AUTOSAR XML (schema 4-2-2)
package /STELLANTIS/EPT/ASWCs
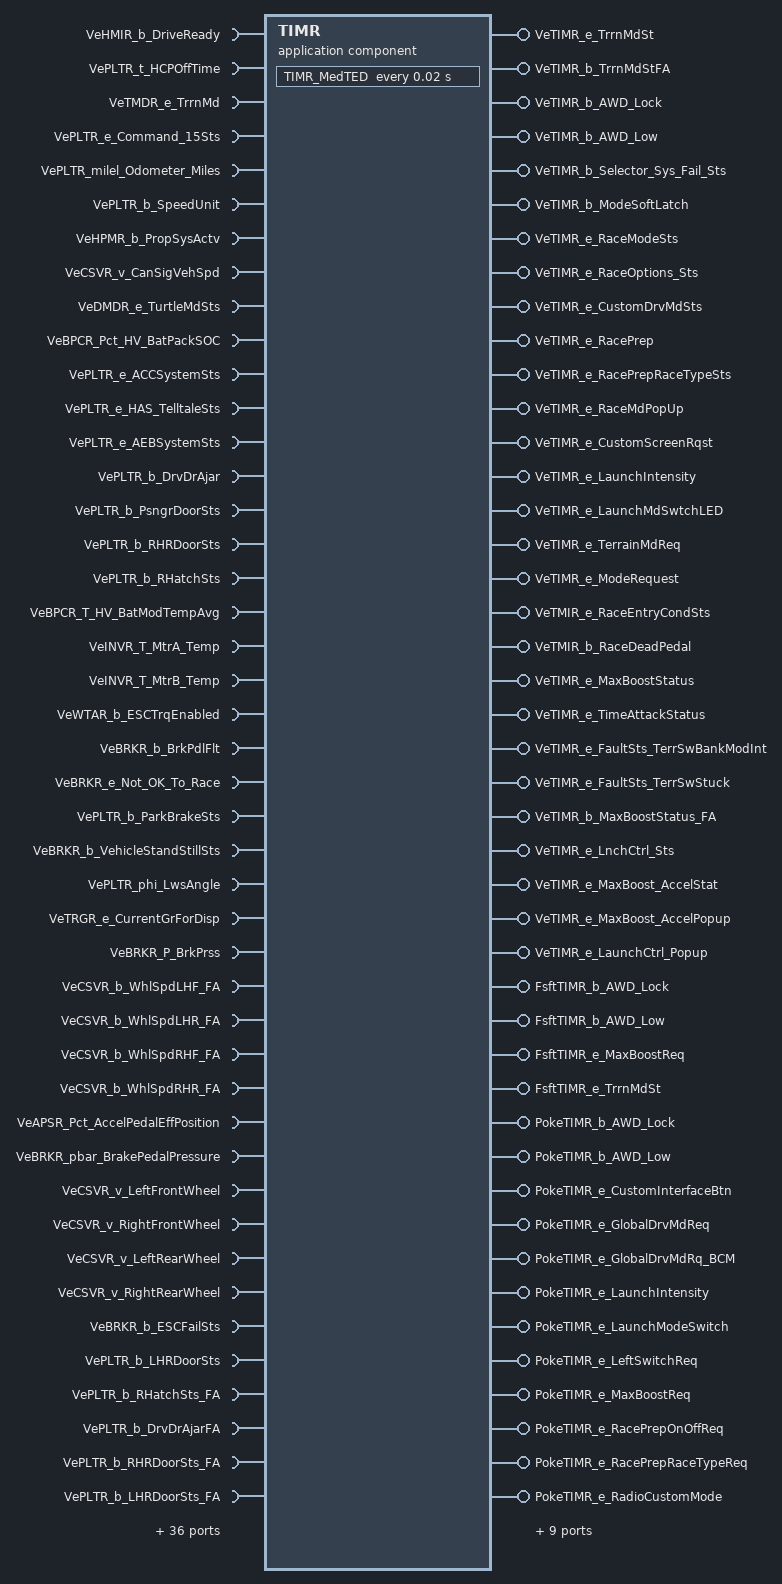
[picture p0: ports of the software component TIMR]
  application sw component type TIMR
    76 x require port:
      VeHMIR_b_DriveReady: nonqueued-receiver-com-spec{data-element=Value, init-value=0}, required-interface=VeHMIR_b_DriveReady
      VePLTR_t_HCPOffTime: nonqueued-receiver-com-spec{data-element=Value, init-value=0}, required-interface=VePLTR_t_HCPOffTime
      VeTMDR_e_TrrnMd: nonqueued-receiver-com-spec{data-element=Value, init-value=CeTMDR_e_NotDefine}, required-interface=VeTMDR_e_TrrnMd
      VePLTR_e_Command_15Sts: variation-point={short-label=vpVePLTR_e_Command_15Sts, sw-syscond=1}, nonqueued-receiver-com-spec{data-element=Value, init-value=CePLTR_e_Not_Pressed}, required-interface=VePLTR_e_Command_15Sts
      VePLTR_milel_Odometer_Miles: nonqueued-receiver-com-spec{data-element=Value, init-value=0}, required-interface=VePLTR_milel_Odometer_Miles
      VePLTR_b_SpeedUnit: variation-point={short-label=vpVePLTR_b_SpeedUnit, sw-syscond=1}, nonqueued-receiver-com-spec{data-element=Value, init-value=0}, required-interface=VePLTR_b_SpeedUnit
      VeHPMR_b_PropSysActv: nonqueued-receiver-com-spec{data-element=Value, init-value=0}, required-interface=VeHPMR_b_PropSysActv
      VeCSVR_v_CanSigVehSpd: nonqueued-receiver-com-spec{data-element=Value, init-value=0}, required-interface=VeCSVR_v_CanSigVehSpd
      VeDMDR_e_TurtleMdSts: nonqueued-receiver-com-spec{data-element=Value, init-value=CeDMDR_e_No_Turtle_Mode}, required-interface=VeDMDR_e_TurtleMdSts
      VeBPCR_Pct_HV_BatPackSOC: nonqueued-receiver-com-spec{data-element=Value, init-value=0}, required-interface=VeBPCR_Pct_HV_BatPackSOC
      VePLTR_e_ACCSystemSts: nonqueued-receiver-com-spec{data-element=Value, init-value=CePLTR_e_Off}, required-interface=VePLTR_e_ACCSystemSts
      VePLTR_e_HAS_TelltaleSts: nonqueued-receiver-com-spec{data-element=Value, init-value=CePLTR_e_HAS_TelltaleSts_OFF}, required-interface=VePLTR_e_HAS_TelltaleSts
      VePLTR_e_AEBSystemSts: nonqueued-receiver-com-spec{data-element=Value, init-value=CePLTR_e_FCW_Off}, required-interface=VePLTR_e_AEBSystemSts
      VePLTR_b_DrvDrAjar: nonqueued-receiver-com-spec{data-element=Value, init-value=0}, required-interface=VePLTR_b_DrvDrAjar
      VePLTR_b_PsngrDoorSts: variation-point={short-label=vpVePLTR_b_PsngrDoorSts, sw-syscond=1}, nonqueued-receiver-com-spec{data-element=Value, init-value=0}, required-interface=VePLTR_b_PsngrDoorSts
      VePLTR_b_RHRDoorSts: variation-point={short-label=vpVePLTR_b_RHRDoorSts, sw-syscond=1}, nonqueued-receiver-com-spec{data-element=Value, init-value=0}, required-interface=VePLTR_b_RHRDoorSts
      VePLTR_b_RHatchSts: variation-point={short-label=vpVePLTR_b_RHatchSts, sw-syscond=1}, nonqueued-receiver-com-spec{data-element=Value, init-value=0}, required-interface=VePLTR_b_RHatchSts
      VeBPCR_T_HV_BatModTempAvg: nonqueued-receiver-com-spec{data-element=Value, init-value=0}, required-interface=VeBPCR_T_HV_BatModTempAvg
      VeINVR_T_MtrA_Temp: nonqueued-receiver-com-spec{data-element=Value, init-value=0}, required-interface=VeINVR_T_MtrA_Temp
      VeINVR_T_MtrB_Temp: nonqueued-receiver-com-spec{data-element=Value, init-value=0}, required-interface=VeINVR_T_MtrB_Temp
      VeWTAR_b_ESCTrqEnabled: variation-point={short-label=vpVeWTAR_b_ESCTrqEnabled, sw-syscond=1}, nonqueued-receiver-com-spec{data-element=Value, init-value=0}, required-interface=VeWTAR_b_ESCTrqEnabled
      VeBRKR_b_BrkPdlFlt: nonqueued-receiver-com-spec{data-element=Value, init-value=0}, required-interface=VeBRKR_b_BrkPdlFlt
      VeBRKR_e_Not_OK_To_Race: variation-point={short-label=vpVeBRKR_e_Not_OK_To_Race, sw-syscond=1}, nonqueued-receiver-com-spec{data-element=Value, init-value=CeBRKR_e_OK}, required-interface=VeBRKR_e_Not_OK_To_Race
      VePLTR_b_ParkBrakeSts: nonqueued-receiver-com-spec{data-element=Value, init-value=0}, required-interface=VePLTR_b_ParkBrakeSts
      VeBRKR_b_VehicleStandStillSts: variation-point={short-label=vpVeBRKR_b_VehicleStandStillSts, sw-syscond=1}, nonqueued-receiver-com-spec{data-element=Value, init-value=0}, required-interface=VeBRKR_b_VehicleStandStillSts
      VePLTR_phi_LwsAngle: nonqueued-receiver-com-spec{data-element=Value, init-value=0}, required-interface=VePLTR_phi_LwsAngle
      VeTRGR_e_CurrentGrForDisp: nonqueued-receiver-com-spec{data-element=Value, init-value=0}, required-interface=VeTRGR_e_CurrentGrForDisp
      VeBRKR_P_BrkPrss: nonqueued-receiver-com-spec{data-element=Value, init-value=0}, required-interface=VeBRKR_P_BrkPrss
      VeCSVR_b_WhlSpdLHF_FA: nonqueued-receiver-com-spec{data-element=Value, init-value=0}, required-interface=VeCSVR_b_WhlSpdLHF_FA
      VeCSVR_b_WhlSpdLHR_FA: nonqueued-receiver-com-spec{data-element=Value, init-value=0}, required-interface=VeCSVR_b_WhlSpdLHR_FA
      VeCSVR_b_WhlSpdRHF_FA: nonqueued-receiver-com-spec{data-element=Value, init-value=0}, required-interface=VeCSVR_b_WhlSpdRHF_FA
      VeCSVR_b_WhlSpdRHR_FA: nonqueued-receiver-com-spec{data-element=Value, init-value=0}, required-interface=VeCSVR_b_WhlSpdRHR_FA
      VeAPSR_Pct_AccelPedalEffPosition: nonqueued-receiver-com-spec{data-element=Value, init-value=0}, required-interface=VeAPSR_Pct_AccelPedalEffPosition
      VeBRKR_pbar_BrakePedalPressure: nonqueued-receiver-com-spec{data-element=Value, init-value=0}, required-interface=VeBRKR_pbar_BrakePedalPressure
      VeCSVR_v_LeftFrontWheel: nonqueued-receiver-com-spec{data-element=Value, init-value=0}, required-interface=VeCSVR_v_LeftFrontWheel
      VeCSVR_v_RightFrontWheel: nonqueued-receiver-com-spec{data-element=Value, init-value=0}, required-interface=VeCSVR_v_RightFrontWheel
      VeCSVR_v_LeftRearWheel: nonqueued-receiver-com-spec{data-element=Value, init-value=0}, required-interface=VeCSVR_v_LeftRearWheel
      VeCSVR_v_RightRearWheel: nonqueued-receiver-com-spec{data-element=Value, init-value=0}, required-interface=VeCSVR_v_RightRearWheel
      VeBRKR_b_ESCFailSts: variation-point={short-label=vpVeBRKR_b_ESCFailSts, sw-syscond=1}, nonqueued-receiver-com-spec{data-element=Value, init-value=0}, required-interface=VeBRKR_b_ESCFailSts
      VePLTR_b_LHRDoorSts: variation-point={short-label=vpVePLTR_b_LHRDoorSts, sw-syscond=1}, nonqueued-receiver-com-spec{data-element=Value, init-value=0}, required-interface=VePLTR_b_LHRDoorSts
      VePLTR_b_RHatchSts_FA: variation-point={short-label=vpVePLTR_b_RHatchSts_FA, sw-syscond=1}, nonqueued-receiver-com-spec{data-element=Value, init-value=0}, required-interface=VePLTR_b_RHatchSts_FA
      VePLTR_b_DrvDrAjarFA: nonqueued-receiver-com-spec{data-element=Value, init-value=0}, required-interface=VePLTR_b_DrvDrAjarFA
      VePLTR_b_RHRDoorSts_FA: variation-point={short-label=vpVePLTR_b_RHRDoorSts_FA, sw-syscond=1}, nonqueued-receiver-com-spec{data-element=Value, init-value=0}, required-interface=VePLTR_b_RHRDoorSts_FA
      VePLTR_b_LHRDoorSts_FA: variation-point={short-label=vpVePLTR_b_LHRDoorSts_FA, sw-syscond=1}, nonqueued-receiver-com-spec{data-element=Value, init-value=0}, required-interface=VePLTR_b_LHRDoorSts_FA
      VePLTR_b_PsngrDoorSts_FA: variation-point={short-label=vpVePLTR_b_PsngrDoorSts_FA, sw-syscond=1}, nonqueued-receiver-com-spec{data-element=Value, init-value=0}, required-interface=VePLTR_b_PsngrDoorSts_FA
      VePLTR_b_SpeedUnit_FA: variation-point={short-label=vpVePLTR_b_SpeedUnit_FA, sw-syscond=1}, nonqueued-receiver-com-spec{data-element=Value, init-value=0}, required-interface=VePLTR_b_SpeedUnit_FA
      VeCSVR_b_CanSigVehSpd_FA: nonqueued-receiver-com-spec{data-element=Value, init-value=0}, required-interface=VeCSVR_b_CanSigVehSpd_FA
      VeBPCR_b_HV_BatPackSOC_FA: nonqueued-receiver-com-spec{data-element=Value, init-value=0}, required-interface=VeBPCR_b_HV_BatPackSOC_FA
      VePLTR_b_ACCSystemSts_FA: nonqueued-receiver-com-spec{data-element=Value, init-value=0}, required-interface=VePLTR_b_ACCSystemSts_FA
      VePLTR_b_HAS_TelltaleSts_FA: nonqueued-receiver-com-spec{data-element=Value, init-value=0}, required-interface=VePLTR_b_HAS_TelltaleSts_FA
      VePLTR_b_AEBSystemSts_FA: nonqueued-receiver-com-spec{data-element=Value, init-value=0}, required-interface=VePLTR_b_AEBSystemSts_FA
      VeBPCR_b_HV_BatModTempAvgFA: nonqueued-receiver-com-spec{data-element=Value, init-value=0}, required-interface=VeBPCR_b_HV_BatModTempAvgFA
      VeINVR_b_MtrB_TempFA: nonqueued-receiver-com-spec{data-element=Value, init-value=0}, required-interface=VeINVR_b_MtrB_TempFA
      VeINVR_b_MtrA_TempFA: nonqueued-receiver-com-spec{data-element=Value, init-value=0}, required-interface=VeINVR_b_MtrA_TempFA
      VeBRKR_b_Not_OK_To_RaceFA: variation-point={short-label=vpVeBRKR_b_Not_OK_To_RaceFA, sw-syscond=1}, nonqueued-receiver-com-spec{data-element=Value, init-value=0}, required-interface=VeBRKR_b_Not_OK_To_RaceFA
      VeSRAR_b_Inhibit_AWD_TerrainMode: nonqueued-receiver-com-spec{data-element=Value, init-value=0}, required-interface=VeSRAR_b_Inhibit_AWD_TerrainMode
      VePRXR_b_Proxi_Custom_Mode: nonqueued-receiver-com-spec{data-element=Value, init-value=0}, required-interface=VePRXR_b_Proxi_Custom_Mode
      VePRXR_b_Proxi_Track_Mode: nonqueued-receiver-com-spec{data-element=Value, init-value=0}, required-interface=VePRXR_b_Proxi_Track_Mode
      VePRXR_e_Axle_Locker_Presence: nonqueued-receiver-com-spec{data-element=Value, init-value=CePRXR_e_ALP_Absent}, required-interface=VePRXR_e_Axle_Locker_Presence
      VePRXR_e_Terrain_Selector_Modes: nonqueued-receiver-com-spec{data-element=Value, init-value=CePRXR_e_Invalid}, required-interface=VePRXR_e_Terrain_Selector_Modes
      VeINVR_T_MtrA_InvrtrTemp: nonqueued-receiver-com-spec{data-element=Value, init-value=0}, required-interface=VeINVR_T_MtrA_InvrtrTemp
      VeINVR_T_MtrB_InvrtrTemp: nonqueued-receiver-com-spec{data-element=Value, init-value=0}, required-interface=VeINVR_T_MtrB_InvrtrTemp
      VeINVR_b_MtrA_InvrtrTempFA: nonqueued-receiver-com-spec{data-element=Value, init-value=0}, required-interface=VeINVR_b_MtrA_InvrtrTempFA
      VeINVR_b_MtrB_InvrtrTempFA: nonqueued-receiver-com-spec{data-element=Value, init-value=0}, required-interface=VeINVR_b_MtrB_InvrtrTempFA
      VePRXR_y_VehicleLineConfiguration: variation-point={short-label=vpVePRXR_y_VehicleLineConfiguration, sw-syscond=1}, nonqueued-receiver-com-spec{data-element=Value, init-value=0}, required-interface=VePRXR_y_VehicleLineConfiguration
      VePMDR_e_PowerModeRaw: variation-point={short-label=vpVePMDR_e_PowerModeRaw, sw-syscond=1}, nonqueued-receiver-com-spec{data-element=Value, init-value=CePMDR_e_PowerMode_Off}, required-interface=VePMDR_e_PowerModeRaw
      VeDFIR_b_IsDiagGlobalConditionsValid: variation-point={short-label=vpVeDFIR_b_IsDiagGlobalConditionsValid, sw-syscond=1}, nonqueued-receiver-com-spec{data-element=Value, init-value=0}, required-interface=VeDFIR_b_IsDiagGlobalConditionsValid
      VeDMAB_y_StatusByte_LostCommBCM: variation-point={short-label=vpVeDMAB_y_StatusByte_LostCommBCM, sw-syscond=1}, nonqueued-receiver-com-spec{data-element=Value, init-value=0}, required-interface=VeDMAB_y_StatusByte_LostCommBCM
      VeDMAB_y_StatusByte_InvData_BCM: variation-point={short-label=vpVeDMAB_y_StatusByte_InvData_BCM, sw-syscond=1}, nonqueued-receiver-com-spec{data-element=Value, init-value=0}, required-interface=VeDMAB_y_StatusByte_InvData_BCM
      VeDMAB_y_StatusByte_HiSpdFD_CAN3CommBus: variation-point={short-label=vpVeDMAB_y_StatusByte_HiSpdFD_CAN3CommBus, sw-syscond=1}, nonqueued-receiver-com-spec{data-element=Value, init-value=0}, required-interface=VeDMAB_y_StatusByte_HiSpdFD_CAN3CommBus
      VeDMAB_y_StatusByte_HiSpdFD_CAN3CommBusPerf: variation-point={short-label=vpVeDMAB_y_StatusByte_HiSpdFD_CAN3CommBusPerf, sw-syscond=1}, nonqueued-receiver-com-spec{data-element=Value, init-value=0}, required-interface=VeDMAB_y_StatusByte_HiSpdFD_CAN3CommBusPerf
      VeDMAB_y_StatusByte_TerrSwBankModInt: variation-point={short-label=vpVeDMAB_y_StatusByte_TerrSwBankModInt, sw-syscond=1}, nonqueued-receiver-com-spec{data-element=Value, init-value=0}, required-interface=VeDMAB_y_StatusByte_TerrSwBankModInt
      VeDMAB_y_StatusByte_TerrSwStuck: variation-point={short-label=vpVeDMAB_y_StatusByte_TerrSwStuck, sw-syscond=1}, nonqueued-receiver-com-spec{data-element=Value, init-value=0}, required-interface=VeDMAB_y_StatusByte_TerrSwStuck
      VeTPCR_b_RacePrepAmbCheck: nonqueued-receiver-com-spec{data-element=Value, init-value=0}, required-interface=VeTPCR_b_RacePrepAmbCheck
      VeTPCR_b_RacePrepEVSysStatus: nonqueued-receiver-com-spec{data-element=Value, init-value=0}, required-interface=VeTPCR_b_RacePrepEVSysStatus
      VeOBCR_b_RacePrepBattLvlSts: nonqueued-receiver-com-spec{data-element=Value, init-value=0}, required-interface=VeOBCR_b_RacePrepBattLvlSts
    49 x provide port:
      VeTIMR_e_TrrnMdSt: nonqueued-sender-com-spec{data-element=Value, init-value=CeTMDR_e_NotDefine}, provided-interface=VeTIMR_e_TrrnMdSt
      VeTIMR_b_TrrnMdStFA: nonqueued-sender-com-spec{data-element=Value, init-value=0}, provided-interface=VeTIMR_b_TrrnMdStFA
      VeTIMR_b_AWD_Lock: nonqueued-sender-com-spec{data-element=Value, init-value=0}, provided-interface=VeTIMR_b_AWD_Lock
      VeTIMR_b_AWD_Low: nonqueued-sender-com-spec{data-element=Value, init-value=0}, provided-interface=VeTIMR_b_AWD_Low
      VeTIMR_b_Selector_Sys_Fail_Sts: nonqueued-sender-com-spec{data-element=Value, init-value=0}, provided-interface=VeTIMR_b_Selector_Sys_Fail_Sts
      VeTIMR_b_ModeSoftLatch: nonqueued-sender-com-spec{data-element=Value, init-value=0}, provided-interface=VeTIMR_b_ModeSoftLatch
      VeTIMR_e_RaceModeSts: nonqueued-sender-com-spec{data-element=Value, init-value=CeTIMR_e_RaceMode_Off}, provided-interface=VeTIMR_e_RaceModeSts
      VeTIMR_e_RaceOptions_Sts: nonqueued-sender-com-spec{data-element=Value, init-value=CeTIMR_e_NoOptionSelected}, provided-interface=VeTIMR_e_RaceOptions_Sts
      VeTIMR_e_CustomDrvMdSts: nonqueued-sender-com-spec{data-element=Value, init-value=CeTMDR_e_NotDefine}, provided-interface=VeTIMR_e_CustomDrvMdSts
      VeTIMR_e_RacePrep: nonqueued-sender-com-spec{data-element=Value, init-value=CeTIMR_e_RacePrep_Off}, provided-interface=VeTIMR_e_RacePrep
      VeTIMR_e_RacePrepRaceTypeSts: nonqueued-sender-com-spec{data-element=Value, init-value=CeTIMR_e_RaceType_Drag}, provided-interface=VeTIMR_e_RacePrepRaceTypeSts
      VeTIMR_e_RaceMdPopUp: nonqueued-sender-com-spec{data-element=Value, init-value=CeTIMR_e_TM0}, provided-interface=VeTIMR_e_RaceMdPopUp
      VeTIMR_e_CustomScreenRqst: nonqueued-sender-com-spec{data-element=Value, init-value=CeTIMR_e_NotActivated}, provided-interface=VeTIMR_e_CustomScreenRqst
      VeTIMR_e_LaunchIntensity: nonqueued-sender-com-spec{data-element=Value, init-value=CeTIMR_e_Max}, provided-interface=VeTIMR_e_LaunchIntensity
      VeTIMR_e_LaunchMdSwtchLED: nonqueued-sender-com-spec{data-element=Value, init-value=CeTIMR_e_LEDOff}, provided-interface=VeTIMR_e_LaunchMdSwtchLED
      VeTIMR_e_TerrainMdReq: nonqueued-sender-com-spec{data-element=Value, init-value=CeTIMR_e_Not_Activated}, provided-interface=VeTIMR_e_TerrainMdReq
      VeTIMR_e_ModeRequest: nonqueued-sender-com-spec{data-element=Value, init-value=CeTMDR_e_NotDefine}, provided-interface=VeTIMR_e_ModeRequest
      VeTMIR_e_RaceEntryCondSts: nonqueued-sender-com-spec{data-element=Value, init-value=CeTIMR_e_RaceEntry_Not_OK}, provided-interface=VeTMIR_e_RaceEntryCondSts
      VeTMIR_b_RaceDeadPedal: nonqueued-sender-com-spec{data-element=Value, init-value=0}, provided-interface=VeTMIR_b_RaceDeadPedal
      VeTIMR_e_MaxBoostStatus: nonqueued-sender-com-spec{data-element=Value, init-value=CeTIMR_e_Boost_Off}, provided-interface=VeTIMR_e_MaxBoostStatus
      VeTIMR_e_TimeAttackStatus: nonqueued-sender-com-spec{data-element=Value, init-value=CeTIMR_e_Boost_Off}, provided-interface=VeTIMR_e_TimeAttackStatus
      VeTIMR_e_FaultSts_TerrSwBankModInt: nonqueued-sender-com-spec{data-element=Value, init-value=CeDFIB_e_Init}, provided-interface=VeTIMR_e_FaultSts_TerrSwBankModInt
      VeTIMR_e_FaultSts_TerrSwStuck: nonqueued-sender-com-spec{data-element=Value, init-value=CeDFIB_e_Init}, provided-interface=VeTIMR_e_FaultSts_TerrSwStuck
      VeTIMR_b_MaxBoostStatus_FA: nonqueued-sender-com-spec{data-element=Value, init-value=0}, provided-interface=VeTIMR_b_MaxBoostStatus_FA
      VeTIMR_e_LnchCtrl_Sts: nonqueued-sender-com-spec{data-element=Value, init-value=CeTIMR_e_NOT_ALLOWED}, provided-interface=VeTIMR_e_LnchCtrl_Sts
      VeTIMR_e_MaxBoost_AccelStat: nonqueued-sender-com-spec{data-element=Value, init-value=CeTIMR_e_NOT_ALLOWED}, provided-interface=VeTIMR_e_MaxBoost_AccelStat
      VeTIMR_e_MaxBoost_AccelPopup: nonqueued-sender-com-spec{data-element=Value, init-value=CeTIMR_e_NONE}, provided-interface=VeTIMR_e_MaxBoost_AccelPopup
      VeTIMR_e_LaunchCtrl_Popup: nonqueued-sender-com-spec{data-element=Value, init-value=CeTIMR_e_NONE}, provided-interface=VeTIMR_e_LaunchCtrl_Popup
      FsftTIMR_b_AWD_Lock: server-com-spec=FsftTIMR_b_AWD_Lock, provided-interface=FsftTIMR_b_AWD_Lock
      FsftTIMR_b_AWD_Low: server-com-spec=FsftTIMR_b_AWD_Low, provided-interface=FsftTIMR_b_AWD_Low
      FsftTIMR_e_MaxBoostReq: server-com-spec=FsftTIMR_e_MaxBoostReq, provided-interface=FsftTIMR_e_MaxBoostReq
      FsftTIMR_e_TrrnMdSt: server-com-spec=FsftTIMR_e_TrrnMdSt, provided-interface=FsftTIMR_e_TrrnMdSt
      PokeTIMR_b_AWD_Lock: server-com-spec{operation=PokeTIMR_b_AWD_Lock, queue-length=1}, provided-interface=PokeTIMR_b_AWD_Lock
      PokeTIMR_b_AWD_Low: server-com-spec{operation=PokeTIMR_b_AWD_Low, queue-length=1}, provided-interface=PokeTIMR_b_AWD_Low
      PokeTIMR_e_CustomInterfaceBtn: server-com-spec{operation=PokeTIMR_e_CustomInterfaceBtn, queue-length=1}, provided-interface=PokeTIMR_e_CustomInterfaceBtn
      PokeTIMR_e_GlobalDrvMdReq: server-com-spec{operation=PokeTIMR_e_GlobalDrvMdReq, queue-length=1}, provided-interface=PokeTIMR_e_GlobalDrvMdReq
      PokeTIMR_e_GlobalDrvMdRq_BCM: server-com-spec{operation=PokeTIMR_e_GlobalDrvMdRq_BCM, queue-length=1}, provided-interface=PokeTIMR_e_GlobalDrvMdRq_BCM
      PokeTIMR_e_LaunchIntensity: server-com-spec{operation=PokeTIMR_e_LaunchIntensity, queue-length=1}, provided-interface=PokeTIMR_e_LaunchIntensity
      PokeTIMR_e_LaunchModeSwitch: server-com-spec{operation=PokeTIMR_e_LaunchModeSwitch, queue-length=1}, provided-interface=PokeTIMR_e_LaunchModeSwitch
      PokeTIMR_e_LeftSwitchReq: server-com-spec{operation=PokeTIMR_e_LeftSwitchReq, queue-length=1}, provided-interface=PokeTIMR_e_LeftSwitchReq
      PokeTIMR_e_MaxBoostReq: server-com-spec{operation=PokeTIMR_e_MaxBoostReq, queue-length=1}, provided-interface=PokeTIMR_e_MaxBoostReq
      PokeTIMR_e_RacePrepOnOffReq: server-com-spec{operation=PokeTIMR_e_RacePrepOnOffReq, queue-length=1}, provided-interface=PokeTIMR_e_RacePrepOnOffReq
      PokeTIMR_e_RacePrepRaceTypeReq: server-com-spec{operation=PokeTIMR_e_RacePrepRaceTypeReq, queue-length=1}, provided-interface=PokeTIMR_e_RacePrepRaceTypeReq
      PokeTIMR_e_RadioCustomMode: server-com-spec{operation=PokeTIMR_e_RadioCustomMode, queue-length=1}, provided-interface=PokeTIMR_e_RadioCustomMode
      PokeTIMR_e_RightSwitchReq: server-com-spec{operation=PokeTIMR_e_RightSwitchReq, queue-length=1}, provided-interface=PokeTIMR_e_RightSwitchReq
      PokeTIMR_e_TimeAttackReq: server-com-spec{operation=PokeTIMR_e_TimeAttackReq, queue-length=1}, provided-interface=PokeTIMR_e_TimeAttackReq
      PokeTIMR_e_TowMdSwitch: server-com-spec{operation=PokeTIMR_e_TowMdSwitch, queue-length=1}, provided-interface=PokeTIMR_e_TowMdSwitch
      PokeTIMR_e_TrrnMdSt: server-com-spec{operation=PokeTIMR_e_TrrnMdSt, queue-length=1}, provided-interface=PokeTIMR_e_TrrnMdSt
      PokeTIMR_e_TrrnToggleMdSwitch: server-com-spec{operation=PokeTIMR_e_TrrnToggleMdSwitch, queue-length=1}, provided-interface=PokeTIMR_e_TrrnToggleMdSwitch
    4 x require port:
      NeTIMR_e_TrrnMdSt_Rx: nv-require-com-spec{init-value=0, variable=NeTIMR_e_TrrnMdSt}, required-interface=NeTIMR_e_TrrnMdSt
      NeTIMR_e_RacePrepMode_Rx: nv-require-com-spec{init-value=CeTIMR_e_RacePrep_Off, variable=NeTIMR_e_RacePrepMode}, required-interface=NeTIMR_e_RacePrepMode
      NeTIMR_b_RacePrepType_Rx: nv-require-com-spec{init-value=0, variable=NeTIMR_b_RacePrepType}, required-interface=NeTIMR_b_RacePrepType
      NeTIMR_b_CustomDrvMdSts_Rx: nv-require-com-spec{init-value=CeTMDR_e_NotDefine, variable=NeTIMR_b_CustomDrvMdSts}, required-interface=NeTIMR_b_CustomDrvMdSts
    4 x provide port:
      NeTIMR_e_TrrnMdSt: nv-provide-com-spec{ram-block-init-value=0, variable=NeTIMR_e_TrrnMdSt}, provided-interface=NeTIMR_e_TrrnMdSt
      NeTIMR_e_RacePrepMode: nv-provide-com-spec{ram-block-init-value=CeTIMR_e_RacePrep_Off, variable=NeTIMR_e_RacePrepMode}, provided-interface=NeTIMR_e_RacePrepMode
      NeTIMR_b_RacePrepType: nv-provide-com-spec{ram-block-init-value=0, variable=NeTIMR_b_RacePrepType}, provided-interface=NeTIMR_b_RacePrepType
      NeTIMR_e_CustomDrvMdSts: nv-provide-com-spec{ram-block-init-value=CeTMDR_e_Street, variable=NeTIMR_e_CustomDrvMdSts}, provided-interface=NeTIMR_e_CustomDrvMdSts
    behavior IB_TIMR: data-type-mapping=msADTtoIDTMapping, handle-termination-and-restart=NO-SUPPORT, included-data-type-set=data-type=TeTIMR_e_DiagStatus
      timing event Event_MedTED: start-on-event=TIMR_MedTED, period=0.02
      21 x operation invoked event:
        Event_FsftTIMR_b_AWD_Lock: start-on-event=FsftTIMR_b_AWD_Lock, operation=FsftTIMR_b_AWD_Lock.FsftTIMR_b_AWD_Lock
        Event_FsftTIMR_b_AWD_Low: start-on-event=FsftTIMR_b_AWD_Low, operation=FsftTIMR_b_AWD_Low.FsftTIMR_b_AWD_Low
        Event_FsftTIMR_e_MaxBoostReq: start-on-event=FsftTIMR_e_MaxBoostReq, operation=FsftTIMR_e_MaxBoostReq.FsftTIMR_e_MaxBoostReq
        Event_FsftTIMR_e_TrrnMdSt: start-on-event=FsftTIMR_e_TrrnMdSt, operation=FsftTIMR_e_TrrnMdSt.FsftTIMR_e_TrrnMdSt
        Event_PokeTIMR_b_AWD_Lock: start-on-event=PokeTIMR_b_AWD_Lock, operation=PokeTIMR_b_AWD_Lock.PokeTIMR_b_AWD_Lock
        Event_PokeTIMR_b_AWD_Low: start-on-event=PokeTIMR_b_AWD_Low, operation=PokeTIMR_b_AWD_Low.PokeTIMR_b_AWD_Low
        Event_PokeTIMR_e_CustomInterfaceBtn: start-on-event=PokeTIMR_e_CustomInterfaceBtn, operation=PokeTIMR_e_CustomInterfaceBtn.PokeTIMR_e_CustomInterfaceBtn
        Event_PokeTIMR_e_GlobalDrvMdReq: start-on-event=PokeTIMR_e_GlobalDrvMdReq, operation=PokeTIMR_e_GlobalDrvMdReq.PokeTIMR_e_GlobalDrvMdReq
        Event_PokeTIMR_e_GlobalDrvMdRq_BCM: start-on-event=PokeTIMR_e_GlobalDrvMdRq_BCM, operation=PokeTIMR_e_GlobalDrvMdRq_BCM.PokeTIMR_e_GlobalDrvMdRq_BCM
        Event_PokeTIMR_e_LaunchIntensity: start-on-event=PokeTIMR_e_LaunchIntensity, operation=PokeTIMR_e_LaunchIntensity.PokeTIMR_e_LaunchIntensity
        Event_PokeTIMR_e_LaunchModeSwitch: start-on-event=PokeTIMR_e_LaunchModeSwitch, operation=PokeTIMR_e_LaunchModeSwitch.PokeTIMR_e_LaunchModeSwitch
        Event_PokeTIMR_e_LeftSwitchReq: start-on-event=PokeTIMR_e_LeftSwitchReq, operation=PokeTIMR_e_LeftSwitchReq.PokeTIMR_e_LeftSwitchReq
        Event_PokeTIMR_e_MaxBoostReq: start-on-event=PokeTIMR_e_MaxBoostReq, operation=PokeTIMR_e_MaxBoostReq.PokeTIMR_e_MaxBoostReq
        Event_PokeTIMR_e_RacePrepOnOffReq: start-on-event=PokeTIMR_e_RacePrepOnOffReq, operation=PokeTIMR_e_RacePrepOnOffReq.PokeTIMR_e_RacePrepOnOffReq
        Event_PokeTIMR_e_RacePrepRaceTypeReq: start-on-event=PokeTIMR_e_RacePrepRaceTypeReq, operation=PokeTIMR_e_RacePrepRaceTypeReq.PokeTIMR_e_RacePrepRaceTypeReq
        Event_PokeTIMR_e_RadioCustomMode: start-on-event=PokeTIMR_e_RadioCustomMode, operation=PokeTIMR_e_RadioCustomMode.PokeTIMR_e_RadioCustomMode
        Event_PokeTIMR_e_RightSwitchReq: start-on-event=PokeTIMR_e_RightSwitchReq, operation=PokeTIMR_e_RightSwitchReq.PokeTIMR_e_RightSwitchReq
        Event_PokeTIMR_e_TimeAttackReq: start-on-event=PokeTIMR_e_TimeAttackReq, operation=PokeTIMR_e_TimeAttackReq.PokeTIMR_e_TimeAttackReq
        Event_PokeTIMR_e_TowMdSwitch: start-on-event=PokeTIMR_e_TowMdSwitch, operation=PokeTIMR_e_TowMdSwitch.PokeTIMR_e_TowMdSwitch
        Event_PokeTIMR_e_TrrnMdSt: start-on-event=PokeTIMR_e_TrrnMdSt, operation=PokeTIMR_e_TrrnMdSt.PokeTIMR_e_TrrnMdSt
        Event_PokeTIMR_e_TrrnToggleMdSwitch: start-on-event=PokeTIMR_e_TrrnToggleMdSwitch, operation=PokeTIMR_e_TrrnToggleMdSwitch.PokeTIMR_e_TrrnToggleMdSwitch
      init event Event_TIMR_ac_Init: start-on-event=TIMR_ac_Init
      init event Event_PwrOn: start-on-event=TIMR_PwrOn
      init event Event_PwrOff: start-on-event=TIMR_PwrOff
      explicit-inter-runnable-variables:
        17 x data, all with category=VALUE, sw-calibration-access=READ-ONLY:
          VeTIMR_e_TrrnMdSt_write_IRV: type=TeTMDR_e_TrrnMd, init-value=CeTMDR_e_NotDefine
          VeTIMR_b_TrrnMdStFA_write_IRV: type=Boolean, init-value=0
          VeTIMR_b_AWD_Lock_write_IRV: type=Boolean, init-value=0
          VeTIMR_b_AWD_Low_write_IRV: type=Boolean, init-value=0
          VeTIMR_e_RightSwitchReq_write_IRV: type=TeTIMR_e_TrrnMdBtnSts, init-value=CeTIMR_e_NotActivated
          VeTIMR_e_LeftSwitchReq_write_IRV: type=TeTIMR_e_TrrnMdBtnSts, init-value=CeTIMR_e_NotActivated
          VeTIMR_e_GlobalDrvMdRq_BCM_write_IRV: type=TeTMDR_e_TrrnMd, init-value=CeTMDR_e_NotDefine
          VeTIMR_e_GlobalDrvMdReq_write_IRV: type=TeTMDR_e_TrrnMd, init-value=CeTMDR_e_NotDefine
          VeTIMR_e_LaunchModeSwitch_write_IRV: type=TeTIMR_e_TrrnMdBtnSts, init-value=CeTIMR_e_NotActivated
          VeTIMR_e_TrrnToggleMdSwitch_write_IRV: type=TeTIMR_e_TrrnTgglSwtSts, init-value=CeTIMR_e_Switch_Not_Activated
          VeTIMR_e_CustomInterfaceBtn_write_IRV: type=TeTIMR_e_TrrnMdBtnSts, init-value=CeTIMR_e_NotActivated
          VeTIMR_e_TowMdSwitch_write_IRV: type=TeTIMR_e_TrrnMdBtnSts, init-value=CeTIMR_e_NotActivated
          VeTIMR_e_LaunchIntensity_write_IRV: type=TeTIMR_e_LaunchIntensity, init-value=CeTIMR_e_Max
          VeTIMR_e_MaxBoostReq_write_IRV: type=TeTIMR_e_BoostRequest, init-value=CeTIMR_e_Boost_Off
          VeTIMR_e_RacePrepOnOffReq_write_IRV: type=Boolean, init-value=0
          VeTIMR_e_RacePrepRaceTypeReq_write_IRV: type=Boolean, init-value=0
          VeTIMR_e_RadioCustomMode_write_IRV: type=TeTMDR_e_TrrnMd, init-value=CeTMDR_e_NotDefine
      25 x runnable:
        TIMR_ac_Init
          data-send-points:
            21 x access:
              OUT_VeTIMR_e_TrrnMdSt_Value: accessed-variable=VeTIMR_e_TrrnMdSt.Value
              OUT_VeTIMR_e_RaceModeSts_Value: accessed-variable=VeTIMR_e_RaceModeSts.Value
              OUT_VeTIMR_e_RaceOptions_Sts_Value: accessed-variable=VeTIMR_e_RaceOptions_Sts.Value
              OUT_VeTIMR_e_CustomDrvMdSts_Value: accessed-variable=VeTIMR_e_CustomDrvMdSts.Value
              OUT_VeTIMR_e_RacePrep_Value: accessed-variable=VeTIMR_e_RacePrep.Value
              OUT_VeTIMR_e_RacePrepRaceTypeSts_Value: accessed-variable=VeTIMR_e_RacePrepRaceTypeSts.Value
              OUT_VeTIMR_e_RaceMdPopUp_Value: accessed-variable=VeTIMR_e_RaceMdPopUp.Value
              OUT_VeTIMR_e_CustomScreenRqst_Value: accessed-variable=VeTIMR_e_CustomScreenRqst.Value
              OUT_VeTIMR_e_LaunchIntensity_Value: accessed-variable=VeTIMR_e_LaunchIntensity.Value
              OUT_VeTIMR_e_LaunchMdSwtchLED_Value: accessed-variable=VeTIMR_e_LaunchMdSwtchLED.Value
              OUT_VeTIMR_e_TerrainMdReq_Value: accessed-variable=VeTIMR_e_TerrainMdReq.Value
              OUT_VeTIMR_e_ModeRequest_Value: accessed-variable=VeTIMR_e_ModeRequest.Value
              OUT_VeTMIR_e_RaceEntryCondSts_Value: accessed-variable=VeTMIR_e_RaceEntryCondSts.Value
              OUT_VeTIMR_e_MaxBoostStatus_Value: accessed-variable=VeTIMR_e_MaxBoostStatus.Value
              OUT_VeTIMR_e_TimeAttackStatus_Value: accessed-variable=VeTIMR_e_TimeAttackStatus.Value
              OUT_VeTIMR_e_FaultSts_TerrSwBankModInt_Value: accessed-variable=VeTIMR_e_FaultSts_TerrSwBankModInt.Value
              OUT_VeTIMR_e_FaultSts_TerrSwStuck_Value: accessed-variable=VeTIMR_e_FaultSts_TerrSwStuck.Value
              OUT_VeTIMR_e_LnchCtrl_Sts_Value: accessed-variable=VeTIMR_e_LnchCtrl_Sts.Value
              OUT_VeTIMR_e_MaxBoost_AccelStat_Value: accessed-variable=VeTIMR_e_MaxBoost_AccelStat.Value
              OUT_VeTIMR_e_MaxBoost_AccelPopup_Value: accessed-variable=VeTIMR_e_MaxBoost_AccelPopup.Value
              OUT_VeTIMR_e_LaunchCtrl_Popup_Value: accessed-variable=VeTIMR_e_LaunchCtrl_Popup.Value
        TIMR_PwrOn
          data-receive-point-by-arguments:
            4 x access:
              IN_NeTIMR_b_CustomDrvMdSts_Rx_NeTIMR_b_CustomDrvMdSts: accessed-variable=NeTIMR_b_CustomDrvMdSts_Rx.NeTIMR_b_CustomDrvMdSts
              IN_NeTIMR_b_RacePrepType_Rx_NeTIMR_b_RacePrepType: accessed-variable=NeTIMR_b_RacePrepType_Rx.NeTIMR_b_RacePrepType
              IN_NeTIMR_e_RacePrepMode_Rx_NeTIMR_e_RacePrepMode: accessed-variable=NeTIMR_e_RacePrepMode_Rx.NeTIMR_e_RacePrepMode
              IN_NeTIMR_e_TrrnMdSt_Rx_NeTIMR_e_TrrnMdSt: accessed-variable=NeTIMR_e_TrrnMdSt_Rx.NeTIMR_e_TrrnMdSt
          data-send-points:
            28 x access:
              OUT_VeTIMR_b_AWD_Lock_Value: accessed-variable=VeTIMR_b_AWD_Lock.Value
              OUT_VeTIMR_b_AWD_Low_Value: accessed-variable=VeTIMR_b_AWD_Low.Value
              OUT_VeTIMR_b_TrrnMdStFA_Value: accessed-variable=VeTIMR_b_TrrnMdStFA.Value
              OUT_VeTIMR_b_Selector_Sys_Fail_Sts_Value: accessed-variable=VeTIMR_b_Selector_Sys_Fail_Sts.Value
              OUT_VeTIMR_b_ModeSoftLatch_Value: accessed-variable=VeTIMR_b_ModeSoftLatch.Value
              OUT_VeTIMR_e_RaceModeSts_Value: accessed-variable=VeTIMR_e_RaceModeSts.Value
              OUT_VeTIMR_e_RaceOptions_Sts_Value: accessed-variable=VeTIMR_e_RaceOptions_Sts.Value
              OUT_VeTIMR_e_TrrnMdSt_Value: accessed-variable=VeTIMR_e_TrrnMdSt.Value
              OUT_VeTIMR_e_RaceMdPopUp_Value: accessed-variable=VeTIMR_e_RaceMdPopUp.Value
              OUT_VeTIMR_e_LaunchMdSwtchLED_Value: accessed-variable=VeTIMR_e_LaunchMdSwtchLED.Value
              OUT_VeTIMR_e_CustomScreenRqst_Value: accessed-variable=VeTIMR_e_CustomScreenRqst.Value
              OUT_VeTIMR_e_LaunchIntensity_Value: accessed-variable=VeTIMR_e_LaunchIntensity.Value
              OUT_VeTIMR_e_TerrainMdReq_Value: accessed-variable=VeTIMR_e_TerrainMdReq.Value
              OUT_VeTIMR_e_ModeRequest_Value: accessed-variable=VeTIMR_e_ModeRequest.Value
              OUT_VeTMIR_e_RaceEntryCondSts_Value: accessed-variable=VeTMIR_e_RaceEntryCondSts.Value
              OUT_VeTMIR_b_RaceDeadPedal_Value: accessed-variable=VeTMIR_b_RaceDeadPedal.Value
              OUT_VeTIMR_e_MaxBoostStatus_Value: accessed-variable=VeTIMR_e_MaxBoostStatus.Value
              OUT_VeTIMR_b_MaxBoostStatus_FA_Value: accessed-variable=VeTIMR_b_MaxBoostStatus_FA.Value
              OUT_VeTIMR_e_TimeAttackStatus_Value: accessed-variable=VeTIMR_e_TimeAttackStatus.Value
              OUT_VeTIMR_e_LnchCtrl_Sts_Value: accessed-variable=VeTIMR_e_LnchCtrl_Sts.Value
              OUT_VeTIMR_e_MaxBoost_AccelStat_Value: accessed-variable=VeTIMR_e_MaxBoost_AccelStat.Value
              OUT_VeTIMR_e_MaxBoost_AccelPopup_Value: accessed-variable=VeTIMR_e_MaxBoost_AccelPopup.Value
              OUT_VeTIMR_e_LaunchCtrl_Popup_Value: accessed-variable=VeTIMR_e_LaunchCtrl_Popup.Value
              OUT_VeTIMR_e_FaultSts_TerrSwBankModInt_Value: accessed-variable=VeTIMR_e_FaultSts_TerrSwBankModInt.Value
              OUT_VeTIMR_e_FaultSts_TerrSwStuck_Value: accessed-variable=VeTIMR_e_FaultSts_TerrSwStuck.Value
              OUT_VeTIMR_e_CustomDrvMdSts_Value: accessed-variable=VeTIMR_e_CustomDrvMdSts.Value
              OUT_VeTIMR_e_RacePrepRaceTypeSts_Value: accessed-variable=VeTIMR_e_RacePrepRaceTypeSts.Value
              OUT_VeTIMR_e_RacePrep_Value: accessed-variable=VeTIMR_e_RacePrep.Value
          written-local-variables:
            13 x access:
              WV_VeTIMR_e_LaunchIntensity_write_IRV: accessed-variable=VeTIMR_e_LaunchIntensity_write_IRV
              WV_VeTIMR_e_MaxBoostReq_write_IRV: accessed-variable=VeTIMR_e_MaxBoostReq_write_IRV
              WV_VeTIMR_e_RadioCustomMode_write_IRV: accessed-variable=VeTIMR_e_RadioCustomMode_write_IRV
              WV_VeTIMR_e_CustomInterfaceBtn_write_IRV: accessed-variable=VeTIMR_e_CustomInterfaceBtn_write_IRV
              WV_VeTIMR_e_GlobalDrvMdRq_BCM_write_IRV: accessed-variable=VeTIMR_e_GlobalDrvMdRq_BCM_write_IRV
              WV_VeTIMR_e_GlobalDrvMdReq_write_IRV: accessed-variable=VeTIMR_e_GlobalDrvMdReq_write_IRV
              WV_VeTIMR_e_LaunchModeSwitch_write_IRV: accessed-variable=VeTIMR_e_LaunchModeSwitch_write_IRV
              WV_VeTIMR_e_LeftSwitchReq_write_IRV: accessed-variable=VeTIMR_e_LeftSwitchReq_write_IRV
              WV_VeTIMR_e_RacePrepOnOffReq_write_IRV: accessed-variable=VeTIMR_e_RacePrepOnOffReq_write_IRV
              WV_VeTIMR_e_RacePrepRaceTypeReq_write_IRV: accessed-variable=VeTIMR_e_RacePrepRaceTypeReq_write_IRV
              WV_VeTIMR_e_RightSwitchReq_write_IRV: accessed-variable=VeTIMR_e_RightSwitchReq_write_IRV
              WV_VeTIMR_e_TowMdSwitch_write_IRV: accessed-variable=VeTIMR_e_TowMdSwitch_write_IRV
              WV_VeTIMR_e_TrrnToggleMdSwitch_write_IRV: accessed-variable=VeTIMR_e_TrrnToggleMdSwitch_write_IRV
        TIMR_MedTED
          data-receive-point-by-arguments:
            76 x access:
              IN_VeAPSR_Pct_AccelPedalEffPosition_Value: accessed-variable=VeAPSR_Pct_AccelPedalEffPosition.Value
              IN_VeBPCR_Pct_HV_BatPackSOC_Value: accessed-variable=VeBPCR_Pct_HV_BatPackSOC.Value
              IN_VeBPCR_T_HV_BatModTempAvg_Value: accessed-variable=VeBPCR_T_HV_BatModTempAvg.Value
              IN_VeBPCR_b_HV_BatModTempAvgFA_Value: accessed-variable=VeBPCR_b_HV_BatModTempAvgFA.Value
              IN_VeBPCR_b_HV_BatPackSOC_FA_Value: accessed-variable=VeBPCR_b_HV_BatPackSOC_FA.Value
              IN_VeBRKR_P_BrkPrss_Value: accessed-variable=VeBRKR_P_BrkPrss.Value
              IN_VeBRKR_b_BrkPdlFlt_Value: accessed-variable=VeBRKR_b_BrkPdlFlt.Value
              IN_VeBRKR_b_ESCFailSts_Value: accessed-variable=VeBRKR_b_ESCFailSts.Value, variation-point={short-label=vpIN_VeBRKR_b_ESCFailSts_Value, sw-syscond=1}
              IN_VeBRKR_b_Not_OK_To_RaceFA_Value: accessed-variable=VeBRKR_b_Not_OK_To_RaceFA.Value, variation-point={short-label=vpIN_VeBRKR_b_Not_OK_To_RaceFA_Value, sw-syscond=1}
              IN_VeBRKR_b_VehicleStandStillSts_Value: accessed-variable=VeBRKR_b_VehicleStandStillSts.Value, variation-point={short-label=vpIN_VeBRKR_b_VehicleStandStillSts_Value, sw-syscond=1}
              IN_VeBRKR_e_Not_OK_To_Race_Value: accessed-variable=VeBRKR_e_Not_OK_To_Race.Value, variation-point={short-label=vpIN_VeBRKR_e_Not_OK_To_Race_Value, sw-syscond=1}
              IN_VeBRKR_pbar_BrakePedalPressure_Value: accessed-variable=VeBRKR_pbar_BrakePedalPressure.Value
              IN_VeCSVR_b_CanSigVehSpd_FA_Value: accessed-variable=VeCSVR_b_CanSigVehSpd_FA.Value
              IN_VeCSVR_b_WhlSpdLHF_FA_Value: accessed-variable=VeCSVR_b_WhlSpdLHF_FA.Value
              IN_VeCSVR_b_WhlSpdLHR_FA_Value: accessed-variable=VeCSVR_b_WhlSpdLHR_FA.Value
              IN_VeCSVR_b_WhlSpdRHF_FA_Value: accessed-variable=VeCSVR_b_WhlSpdRHF_FA.Value
              IN_VeCSVR_b_WhlSpdRHR_FA_Value: accessed-variable=VeCSVR_b_WhlSpdRHR_FA.Value
              IN_VeCSVR_v_CanSigVehSpd_Value: accessed-variable=VeCSVR_v_CanSigVehSpd.Value
              IN_VeCSVR_v_LeftFrontWheel_Value: accessed-variable=VeCSVR_v_LeftFrontWheel.Value
              IN_VeCSVR_v_LeftRearWheel_Value: accessed-variable=VeCSVR_v_LeftRearWheel.Value
              IN_VeCSVR_v_RightFrontWheel_Value: accessed-variable=VeCSVR_v_RightFrontWheel.Value
              IN_VeCSVR_v_RightRearWheel_Value: accessed-variable=VeCSVR_v_RightRearWheel.Value
              IN_VeDFIR_b_IsDiagGlobalConditionsValid_Value: accessed-variable=VeDFIR_b_IsDiagGlobalConditionsValid.Value, variation-point={short-label=vpIN_VeDFIR_b_IsDiagGlobalConditionsValid_Value, sw-syscond=1}
              IN_VeDMAB_y_StatusByte_HiSpdFD_CAN3CommBus_Value: accessed-variable=VeDMAB_y_StatusByte_HiSpdFD_CAN3CommBus.Value, variation-point={short-label=vpIN_VeDMAB_y_StatusByte_HiSpdFD_CAN3CommBus_Value, sw-syscond=1}
              IN_VeDMAB_y_StatusByte_HiSpdFD_CAN3CommBusPerf_Value: accessed-variable=VeDMAB_y_StatusByte_HiSpdFD_CAN3CommBusPerf.Value, variation-point={short-label=vpIN_VeDMAB_y_StatusByte_HiSpdFD_CAN3CommBusPerf_Value, sw-syscond=1}
              IN_VeDMAB_y_StatusByte_InvData_BCM_Value: accessed-variable=VeDMAB_y_StatusByte_InvData_BCM.Value, variation-point={short-label=vpIN_VeDMAB_y_StatusByte_InvData_BCM_Value, sw-syscond=1}
              IN_VeDMAB_y_StatusByte_LostCommBCM_Value: accessed-variable=VeDMAB_y_StatusByte_LostCommBCM.Value, variation-point={short-label=vpIN_VeDMAB_y_StatusByte_LostCommBCM_Value, sw-syscond=1}
              IN_VeDMAB_y_StatusByte_TerrSwBankModInt_Value: accessed-variable=VeDMAB_y_StatusByte_TerrSwBankModInt.Value, variation-point={short-label=vpIN_VeDMAB_y_StatusByte_TerrSwBankModInt_Value, sw-syscond=1}
              IN_VeDMAB_y_StatusByte_TerrSwStuck_Value: accessed-variable=VeDMAB_y_StatusByte_TerrSwStuck.Value, variation-point={short-label=vpIN_VeDMAB_y_StatusByte_TerrSwStuck_Value, sw-syscond=1}
              IN_VeDMDR_e_TurtleMdSts_Value: accessed-variable=VeDMDR_e_TurtleMdSts.Value
              IN_VeHMIR_b_DriveReady_Value: accessed-variable=VeHMIR_b_DriveReady.Value
              IN_VeHPMR_b_PropSysActv_Value: accessed-variable=VeHPMR_b_PropSysActv.Value
              IN_VeINVR_T_MtrA_InvrtrTemp_Value: accessed-variable=VeINVR_T_MtrA_InvrtrTemp.Value
              IN_VeINVR_T_MtrA_Temp_Value: accessed-variable=VeINVR_T_MtrA_Temp.Value
              IN_VeINVR_T_MtrB_InvrtrTemp_Value: accessed-variable=VeINVR_T_MtrB_InvrtrTemp.Value
              IN_VeINVR_T_MtrB_Temp_Value: accessed-variable=VeINVR_T_MtrB_Temp.Value
              IN_VeINVR_b_MtrA_InvrtrTempFA_Value: accessed-variable=VeINVR_b_MtrA_InvrtrTempFA.Value
              IN_VeINVR_b_MtrA_TempFA_Value: accessed-variable=VeINVR_b_MtrA_TempFA.Value
              IN_VeINVR_b_MtrB_InvrtrTempFA_Value: accessed-variable=VeINVR_b_MtrB_InvrtrTempFA.Value
              IN_VeINVR_b_MtrB_TempFA_Value: accessed-variable=VeINVR_b_MtrB_TempFA.Value
              IN_VeOBCR_b_RacePrepBattLvlSts_Value: accessed-variable=VeOBCR_b_RacePrepBattLvlSts.Value
              IN_VePLTR_b_ACCSystemSts_FA_Value: accessed-variable=VePLTR_b_ACCSystemSts_FA.Value
              IN_VePLTR_b_AEBSystemSts_FA_Value: accessed-variable=VePLTR_b_AEBSystemSts_FA.Value
              IN_VePLTR_b_DrvDrAjar_Value: accessed-variable=VePLTR_b_DrvDrAjar.Value
              IN_VePLTR_b_DrvDrAjarFA_Value: accessed-variable=VePLTR_b_DrvDrAjarFA.Value
              IN_VePLTR_b_HAS_TelltaleSts_FA_Value: accessed-variable=VePLTR_b_HAS_TelltaleSts_FA.Value
              IN_VePLTR_b_LHRDoorSts_Value: accessed-variable=VePLTR_b_LHRDoorSts.Value, variation-point={short-label=vpIN_VePLTR_b_LHRDoorSts_Value, sw-syscond=1}
              IN_VePLTR_b_LHRDoorSts_FA_Value: accessed-variable=VePLTR_b_LHRDoorSts_FA.Value, variation-point={short-label=vpIN_VePLTR_b_LHRDoorSts_FA_Value, sw-syscond=1}
              IN_VePLTR_b_ParkBrakeSts_Value: accessed-variable=VePLTR_b_ParkBrakeSts.Value
              IN_VePLTR_b_PsngrDoorSts_Value: accessed-variable=VePLTR_b_PsngrDoorSts.Value, variation-point={short-label=vpIN_VePLTR_b_PsngrDoorSts_Value, sw-syscond=1}
              IN_VePLTR_b_PsngrDoorSts_FA_Value: accessed-variable=VePLTR_b_PsngrDoorSts_FA.Value, variation-point={short-label=vpIN_VePLTR_b_PsngrDoorSts_FA_Value, sw-syscond=1}
              IN_VePLTR_b_RHRDoorSts_Value: accessed-variable=VePLTR_b_RHRDoorSts.Value, variation-point={short-label=vpIN_VePLTR_b_RHRDoorSts_Value, sw-syscond=1}
              IN_VePLTR_b_RHRDoorSts_FA_Value: accessed-variable=VePLTR_b_RHRDoorSts_FA.Value, variation-point={short-label=vpIN_VePLTR_b_RHRDoorSts_FA_Value, sw-syscond=1}
              IN_VePLTR_b_RHatchSts_Value: accessed-variable=VePLTR_b_RHatchSts.Value, variation-point={short-label=vpIN_VePLTR_b_RHatchSts_Value, sw-syscond=1}
              IN_VePLTR_b_RHatchSts_FA_Value: accessed-variable=VePLTR_b_RHatchSts_FA.Value, variation-point={short-label=vpIN_VePLTR_b_RHatchSts_FA_Value, sw-syscond=1}
              IN_VePLTR_b_SpeedUnit_Value: accessed-variable=VePLTR_b_SpeedUnit.Value, variation-point={short-label=vpIN_VePLTR_b_SpeedUnit_Value, sw-syscond=1}
              IN_VePLTR_b_SpeedUnit_FA_Value: accessed-variable=VePLTR_b_SpeedUnit_FA.Value, variation-point={short-label=vpIN_VePLTR_b_SpeedUnit_FA_Value, sw-syscond=1}
              IN_VePLTR_e_ACCSystemSts_Value: accessed-variable=VePLTR_e_ACCSystemSts.Value
              IN_VePLTR_e_AEBSystemSts_Value: accessed-variable=VePLTR_e_AEBSystemSts.Value
              IN_VePLTR_e_Command_15Sts_Value: accessed-variable=VePLTR_e_Command_15Sts.Value, variation-point={short-label=vpIN_VePLTR_e_Command_15Sts_Value, sw-syscond=1}
              IN_VePLTR_e_HAS_TelltaleSts_Value: accessed-variable=VePLTR_e_HAS_TelltaleSts.Value
              IN_VePLTR_milel_Odometer_Miles_Value: accessed-variable=VePLTR_milel_Odometer_Miles.Value
              IN_VePLTR_phi_LwsAngle_Value: accessed-variable=VePLTR_phi_LwsAngle.Value
              IN_VePLTR_t_HCPOffTime_Value: accessed-variable=VePLTR_t_HCPOffTime.Value
              IN_VePMDR_e_PowerModeRaw_Value: accessed-variable=VePMDR_e_PowerModeRaw.Value, variation-point={short-label=vpIN_VePMDR_e_PowerModeRaw_Value, sw-syscond=1}
              IN_VePRXR_b_Proxi_Custom_Mode_Value: accessed-variable=VePRXR_b_Proxi_Custom_Mode.Value
              IN_VePRXR_b_Proxi_Track_Mode_Value: accessed-variable=VePRXR_b_Proxi_Track_Mode.Value
              IN_VePRXR_e_Axle_Locker_Presence_Value: accessed-variable=VePRXR_e_Axle_Locker_Presence.Value
              IN_VePRXR_e_Terrain_Selector_Modes_Value: accessed-variable=VePRXR_e_Terrain_Selector_Modes.Value
              IN_VePRXR_y_VehicleLineConfiguration_Value: accessed-variable=VePRXR_y_VehicleLineConfiguration.Value, variation-point={short-label=vpIN_VePRXR_y_VehicleLineConfiguration_Value, sw-syscond=1}
              IN_VeSRAR_b_Inhibit_AWD_TerrainMode_Value: accessed-variable=VeSRAR_b_Inhibit_AWD_TerrainMode.Value
              IN_VeTMDR_e_TrrnMd_Value: accessed-variable=VeTMDR_e_TrrnMd.Value
              IN_VeTPCR_b_RacePrepAmbCheck_Value: accessed-variable=VeTPCR_b_RacePrepAmbCheck.Value
              IN_VeTPCR_b_RacePrepEVSysStatus_Value: accessed-variable=VeTPCR_b_RacePrepEVSysStatus.Value
              IN_VeTRGR_e_CurrentGrForDisp_Value: accessed-variable=VeTRGR_e_CurrentGrForDisp.Value
              IN_VeWTAR_b_ESCTrqEnabled_Value: accessed-variable=VeWTAR_b_ESCTrqEnabled.Value, variation-point={short-label=vpIN_VeWTAR_b_ESCTrqEnabled_Value, sw-syscond=1}
          data-send-points:
            26 x access:
              OUT_VeTIMR_b_AWD_Lock_Value: accessed-variable=VeTIMR_b_AWD_Lock.Value
              OUT_VeTIMR_b_AWD_Low_Value: accessed-variable=VeTIMR_b_AWD_Low.Value
              OUT_VeTIMR_b_TrrnMdStFA_Value: accessed-variable=VeTIMR_b_TrrnMdStFA.Value
              OUT_VeTIMR_b_Selector_Sys_Fail_Sts_Value: accessed-variable=VeTIMR_b_Selector_Sys_Fail_Sts.Value
              OUT_VeTIMR_b_ModeSoftLatch_Value: accessed-variable=VeTIMR_b_ModeSoftLatch.Value
              OUT_VeTIMR_e_RaceModeSts_Value: accessed-variable=VeTIMR_e_RaceModeSts.Value
              OUT_VeTIMR_e_RaceOptions_Sts_Value: accessed-variable=VeTIMR_e_RaceOptions_Sts.Value
              OUT_VeTIMR_e_TrrnMdSt_Value: accessed-variable=VeTIMR_e_TrrnMdSt.Value
              OUT_VeTIMR_e_RaceMdPopUp_Value: accessed-variable=VeTIMR_e_RaceMdPopUp.Value
              OUT_VeTIMR_e_LaunchMdSwtchLED_Value: accessed-variable=VeTIMR_e_LaunchMdSwtchLED.Value
              OUT_VeTIMR_e_CustomScreenRqst_Value: accessed-variable=VeTIMR_e_CustomScreenRqst.Value
              OUT_VeTIMR_e_LaunchIntensity_Value: accessed-variable=VeTIMR_e_LaunchIntensity.Value
              OUT_VeTIMR_e_TerrainMdReq_Value: accessed-variable=VeTIMR_e_TerrainMdReq.Value
              OUT_VeTIMR_e_ModeRequest_Value: accessed-variable=VeTIMR_e_ModeRequest.Value
              OUT_VeTMIR_e_RaceEntryCondSts_Value: accessed-variable=VeTMIR_e_RaceEntryCondSts.Value
              OUT_VeTMIR_b_RaceDeadPedal_Value: accessed-variable=VeTMIR_b_RaceDeadPedal.Value
              OUT_VeTIMR_e_LnchCtrl_Sts_Value: accessed-variable=VeTIMR_e_LnchCtrl_Sts.Value
              OUT_VeTIMR_e_MaxBoost_AccelStat_Value: accessed-variable=VeTIMR_e_MaxBoost_AccelStat.Value
              OUT_VeTIMR_e_MaxBoost_AccelPopup_Value: accessed-variable=VeTIMR_e_MaxBoost_AccelPopup.Value
              OUT_VeTIMR_e_LaunchCtrl_Popup_Value: accessed-variable=VeTIMR_e_LaunchCtrl_Popup.Value
              OUT_VeTIMR_e_MaxBoostStatus_Value: accessed-variable=VeTIMR_e_MaxBoostStatus.Value
              OUT_VeTIMR_e_FaultSts_TerrSwBankModInt_Value: accessed-variable=VeTIMR_e_FaultSts_TerrSwBankModInt.Value
              OUT_VeTIMR_e_FaultSts_TerrSwStuck_Value: accessed-variable=VeTIMR_e_FaultSts_TerrSwStuck.Value
              OUT_VeTIMR_e_RacePrepRaceTypeSts_Value: accessed-variable=VeTIMR_e_RacePrepRaceTypeSts.Value
              OUT_VeTIMR_e_RacePrep_Value: accessed-variable=VeTIMR_e_RacePrep.Value
              OUT_VeTIMR_e_CustomDrvMdSts_Value: accessed-variable=VeTIMR_e_CustomDrvMdSts.Value
          read-local-variables:
            16 x access:
              RV_VeTIMR_b_AWD_Lock_write_IRV: accessed-variable=VeTIMR_b_AWD_Lock_write_IRV
              RV_VeTIMR_b_AWD_Low_write_IRV: accessed-variable=VeTIMR_b_AWD_Low_write_IRV
              RV_VeTIMR_b_TrrnMdStFA_write_IRV: accessed-variable=VeTIMR_b_TrrnMdStFA_write_IRV
              RV_VeTIMR_e_CustomInterfaceBtn_write_IRV: accessed-variable=VeTIMR_e_CustomInterfaceBtn_write_IRV
              RV_VeTIMR_e_GlobalDrvMdReq_write_IRV: accessed-variable=VeTIMR_e_GlobalDrvMdReq_write_IRV
              RV_VeTIMR_e_GlobalDrvMdRq_BCM_write_IRV: accessed-variable=VeTIMR_e_GlobalDrvMdRq_BCM_write_IRV
              RV_VeTIMR_e_LaunchIntensity_write_IRV: accessed-variable=VeTIMR_e_LaunchIntensity_write_IRV, variation-point={short-label=vpRV_VeTIMR_e_LaunchIntensity_write_IRV, sw-syscond=1}
              RV_VeTIMR_e_LaunchModeSwitch_write_IRV: accessed-variable=VeTIMR_e_LaunchModeSwitch_write_IRV
              RV_VeTIMR_e_LeftSwitchReq_write_IRV: accessed-variable=VeTIMR_e_LeftSwitchReq_write_IRV
              RV_VeTIMR_e_RacePrepOnOffReq_write_IRV: accessed-variable=VeTIMR_e_RacePrepOnOffReq_write_IRV
              RV_VeTIMR_e_RacePrepRaceTypeReq_write_IRV: accessed-variable=VeTIMR_e_RacePrepRaceTypeReq_write_IRV
              RV_VeTIMR_e_RadioCustomMode_write_IRV: accessed-variable=VeTIMR_e_RadioCustomMode_write_IRV
              RV_VeTIMR_e_RightSwitchReq_write_IRV: accessed-variable=VeTIMR_e_RightSwitchReq_write_IRV
              RV_VeTIMR_e_TowMdSwitch_write_IRV: accessed-variable=VeTIMR_e_TowMdSwitch_write_IRV
              RV_VeTIMR_e_TrrnMdSt_write_IRV: accessed-variable=VeTIMR_e_TrrnMdSt_write_IRV
              RV_VeTIMR_e_TrrnToggleMdSwitch_write_IRV: accessed-variable=VeTIMR_e_TrrnToggleMdSwitch_write_IRV
        TIMR_PwrOff
          data-send-points:
            4 x access:
              OUT_NeTIMR_e_TrrnMdSt_NeTIMR_e_TrrnMdSt: accessed-variable=NeTIMR_e_TrrnMdSt.NeTIMR_e_TrrnMdSt
              OUT_NeTIMR_e_RacePrepMode_NeTIMR_e_RacePrepMode: accessed-variable=NeTIMR_e_RacePrepMode.NeTIMR_e_RacePrepMode
              OUT_NeTIMR_b_RacePrepType_NeTIMR_b_RacePrepType: accessed-variable=NeTIMR_b_RacePrepType.NeTIMR_b_RacePrepType
              OUT_NeTIMR_e_CustomDrvMdSts_NeTIMR_e_CustomDrvMdSts: accessed-variable=NeTIMR_e_CustomDrvMdSts.NeTIMR_e_CustomDrvMdSts
        FsftTIMR_b_AWD_Lock
          written-local-variables:
            access WV_VeTIMR_b_AWD_Lock_write_IRV: accessed-variable=VeTIMR_b_AWD_Lock_write_IRV
        FsftTIMR_b_AWD_Low
          written-local-variables:
            access WV_VeTIMR_b_AWD_Low_write_IRV: accessed-variable=VeTIMR_b_AWD_Low_write_IRV
        FsftTIMR_e_MaxBoostReq
          data-send-points:
            access OUT_VeTIMR_b_MaxBoostStatus_FA_Value: accessed-variable=VeTIMR_b_MaxBoostStatus_FA.Value
        FsftTIMR_e_TrrnMdSt
          written-local-variables:
            access WV_VeTIMR_b_TrrnMdStFA_write_IRV: accessed-variable=VeTIMR_b_TrrnMdStFA_write_IRV
            access WV_VeTIMR_e_TrrnMdSt_write_IRV: accessed-variable=VeTIMR_e_TrrnMdSt_write_IRV
        PokeTIMR_b_AWD_Lock
          written-local-variables:
            access WV_VeTIMR_b_AWD_Lock_write_IRV: accessed-variable=VeTIMR_b_AWD_Lock_write_IRV
        PokeTIMR_b_AWD_Low
          written-local-variables:
            access WV_VeTIMR_b_AWD_Low_write_IRV: accessed-variable=VeTIMR_b_AWD_Low_write_IRV
        PokeTIMR_e_CustomInterfaceBtn
          written-local-variables:
            access WV_VeTIMR_e_CustomInterfaceBtn_write_IRV: accessed-variable=VeTIMR_e_CustomInterfaceBtn_write_IRV
        PokeTIMR_e_GlobalDrvMdReq
          written-local-variables:
            access WV_VeTIMR_e_GlobalDrvMdReq_write_IRV: accessed-variable=VeTIMR_e_GlobalDrvMdReq_write_IRV
        PokeTIMR_e_GlobalDrvMdRq_BCM
          written-local-variables:
            access WV_VeTIMR_e_GlobalDrvMdRq_BCM_write_IRV: accessed-variable=VeTIMR_e_GlobalDrvMdRq_BCM_write_IRV
        PokeTIMR_e_LaunchIntensity
          written-local-variables:
            access WV_VeTIMR_e_LaunchIntensity_write_IRV: accessed-variable=VeTIMR_e_LaunchIntensity_write_IRV, variation-point={short-label=vpWV_VeTIMR_e_LaunchIntensity_write_IRV, sw-syscond=1}
        PokeTIMR_e_LaunchModeSwitch
          written-local-variables:
            access WV_VeTIMR_e_LaunchModeSwitch_write_IRV: accessed-variable=VeTIMR_e_LaunchModeSwitch_write_IRV
        PokeTIMR_e_LeftSwitchReq
          written-local-variables:
            access WV_VeTIMR_e_LeftSwitchReq_write_IRV: accessed-variable=VeTIMR_e_LeftSwitchReq_write_IRV
        PokeTIMR_e_MaxBoostReq
          data-send-points:
            access OUT_VeTIMR_b_MaxBoostStatus_FA_Value: accessed-variable=VeTIMR_b_MaxBoostStatus_FA.Value
        PokeTIMR_e_RacePrepOnOffReq
          written-local-variables:
            access WV_VeTIMR_e_RacePrepOnOffReq_write_IRV: accessed-variable=VeTIMR_e_RacePrepOnOffReq_write_IRV
        PokeTIMR_e_RacePrepRaceTypeReq
          written-local-variables:
            access WV_VeTIMR_e_RacePrepRaceTypeReq_write_IRV: accessed-variable=VeTIMR_e_RacePrepRaceTypeReq_write_IRV
        PokeTIMR_e_RadioCustomMode
          written-local-variables:
            access WV_VeTIMR_e_RadioCustomMode_write_IRV: accessed-variable=VeTIMR_e_RadioCustomMode_write_IRV
        PokeTIMR_e_RightSwitchReq
          written-local-variables:
            access WV_VeTIMR_e_RightSwitchReq_write_IRV: accessed-variable=VeTIMR_e_RightSwitchReq_write_IRV
        PokeTIMR_e_TimeAttackReq
          data-send-points:
            access OUT_VeTIMR_e_TimeAttackStatus_Value: accessed-variable=VeTIMR_e_TimeAttackStatus.Value
        PokeTIMR_e_TowMdSwitch
          written-local-variables:
            access WV_VeTIMR_e_TowMdSwitch_write_IRV: accessed-variable=VeTIMR_e_TowMdSwitch_write_IRV
        PokeTIMR_e_TrrnMdSt
          written-local-variables:
            access WV_VeTIMR_b_TrrnMdStFA_write_IRV: accessed-variable=VeTIMR_b_TrrnMdStFA_write_IRV
            access WV_VeTIMR_e_TrrnMdSt_write_IRV: accessed-variable=VeTIMR_e_TrrnMdSt_write_IRV
        PokeTIMR_e_TrrnToggleMdSwitch
          written-local-variables:
            access WV_VeTIMR_e_TrrnToggleMdSwitch_write_IRV: accessed-variable=VeTIMR_e_TrrnToggleMdSwitch_write_IRV
      variation point proxy Variant_TIMR_1: category=CONDITION, condition-access=0
      variation point proxy Variant_TIMR_2: category=CONDITION, condition-access=1
      variation point proxy Variant_TIMR_3: category=CONDITION, condition-access=0
